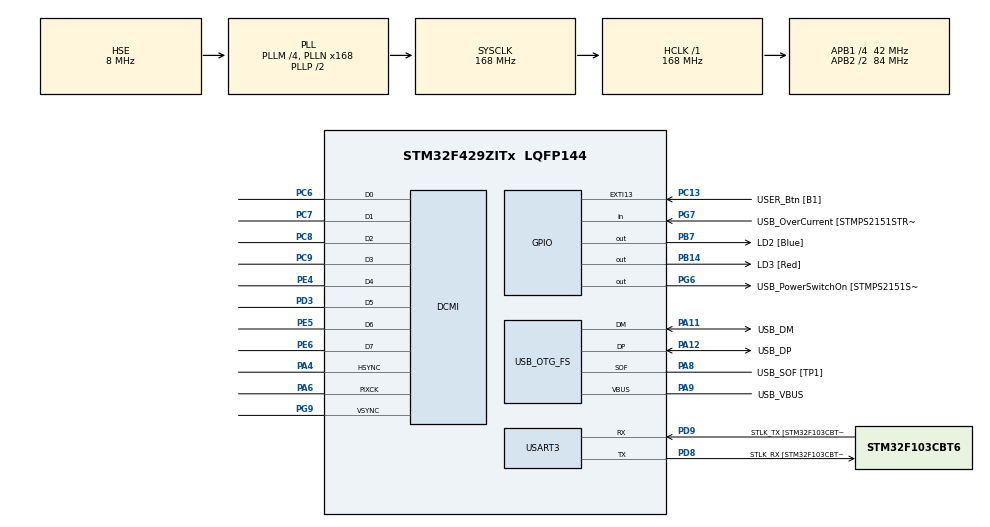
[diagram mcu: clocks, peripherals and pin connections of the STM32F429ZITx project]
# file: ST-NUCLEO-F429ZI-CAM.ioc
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Mcu.Family=STM32F4
Mcu.Name=STM32F429ZITx
Mcu.Package=LQFP144
NVIC.PriorityGroup=NVIC_PRIORITYGROUP_4
PA11.GPIO_Label=USB_DM
PA11.Mode=Device_Only
PA11.Signal=USB_OTG_FS_DM
PA12.GPIO_Label=USB_DP
PA12.Mode=Device_Only
PA12.Signal=USB_OTG_FS_DP
PA13.GPIO_Label=TMS
PA13.Mode=Serial_Wire
PA13.Signal=SYS_JTMS-SWDIO
PA14.GPIO_Label=TCK
PA14.Mode=Serial_Wire
PA14.Signal=SYS_JTCK-SWCLK
PA4.Mode=Slave_8_bits_External_Synchro
PA4.Signal=DCMI_HSYNC
PA6.Mode=Slave_8_bits_External_Synchro
PA6.Signal=DCMI_PIXCK
PA8.GPIO_Label=USB_SOF [TP1]
PA8.Mode=Activate_SOF_FS
PA8.Signal=USB_OTG_FS_SOF
PA9.GPIO_Label=USB_VBUS
PA9.Mode=Activate_VBUS
PA9.Signal=USB_OTG_FS_VBUS
PB14.GPIO_Label=LD3 [Red]
PB14.Signal=GPIO_Output
PB7.GPIO_Label=LD2 [Blue]
PB7.Signal=GPIO_Output
PC13.GPIO_Label=USER_Btn [B1]
PC13.Signal=GPXTI13
PC14/OSC32_IN.Mode=LSE-External-Oscillator
PC14/OSC32_IN.Signal=RCC_OSC32_IN
PC15/OSC32_OUT.Mode=LSE-External-Oscillator
PC15/OSC32_OUT.Signal=RCC_OSC32_OUT
PC6.Mode=Slave_8_bits_External_Synchro
PC6.Signal=DCMI_D0
PC7.Mode=Slave_8_bits_External_Synchro
PC7.Signal=DCMI_D1
PC8.Mode=Slave_8_bits_External_Synchro
PC8.Signal=DCMI_D2
PC9.Mode=Slave_8_bits_External_Synchro
PC9.Signal=DCMI_D3
PD3.Mode=Slave_8_bits_External_Synchro
PD3.Signal=DCMI_D5
PD8.GPIO_Label=STLK_RX [STM32F103CBT6_PA3]
PD8.Mode=Asynchronous
PD8.Signal=USART3_TX
PD9.GPIO_Label=STLK_TX [STM32F103CBT6_PA2]
PD9.Mode=Asynchronous
PD9.Signal=USART3_RX
PE4.Mode=Slave_8_bits_External_Synchro
PE4.Signal=DCMI_D4
PE5.Mode=Slave_8_bits_External_Synchro
PE5.Signal=DCMI_D6
PE6.Mode=Slave_8_bits_External_Synchro
PE6.Signal=DCMI_D7
PG6.GPIO_Label=USB_PowerSwitchOn [STMPS2151STR_EN]
PG6.Signal=GPIO_Output
PG7.GPIO_Label=USB_OverCurrent [STMPS2151STR_FAULT]
PG7.Signal=GPIO_Input
PG9.Mode=Slave_8_bits_External_Synchro
PG9.Signal=DCMI_VSYNC
PH0/OSC_IN.GPIO_Label=MCO [STM32F103CBT6_PA8]
PH0/OSC_IN.Mode=HSE-External-Clock-Source
PH0/OSC_IN.Signal=RCC_OSC_IN
PH1/OSC_OUT.Mode=HSE-External-Clock-Source
PH1/OSC_OUT.Signal=RCC_OSC_OUT
ProjectManager.HeapSize=0x1200
ProjectManager.StackSize=0x1400
ProjectManager.TargetToolchain=MDK-ARM V5
RCC.48MHZClocksFreq_Value=48000000
RCC.AHBFreq_Value=168000000
RCC.APB1CLKDivider=RCC_HCLK_DIV4
RCC.APB1Freq_Value=42000000
RCC.APB1TimFreq_Value=84000000
RCC.APB2CLKDivider=RCC_HCLK_DIV2
RCC.APB2Freq_Value=84000000
RCC.APB2TimCLKDivider=2
RCC.APB2TimFreq_Value=168000000
RCC.CortexFreq_Value=168000000
RCC.HCLKFreq_Value=168000000
RCC.HSE_VALUE=8000000
RCC.HSI_VALUE=16000000
RCC.PLLM=4
RCC.PLLMUL=RCC_PLL_MUL9
RCC.PLLN=168
RCC.PLLQ=7
RCC.PRESCALERUSB=RCC_USBCLKSOURCE_PLL_DIV1_5
RCC.SYSCLKFreq_VALUE=168000000
RCC.SYSCLKSource=RCC_SYSCLKSOURCE_PLLCLK
RCC.SYSCLKSourceVirtual=RCC_SYSCLKSOURCE_PLLCLK
RCC.USBFreq_Value=48000000
RCC.VCOOutputFreq_Value=336000000
USART3.VirtualMode=VM_ASYNC
USB_DEVICE.CLASS_NAME_FS=AUDIO
USB_DEVICE.VirtualMode-AUDIO_FS=Audio
USB_DEVICE.VirtualModeFS=Audio_FS
USB_OTG_FS.VirtualMode=Device_Only
VP_USB_DEVICE_VS_USB_DEVICE_AUDIO_FS.Mode=AUDIO_FS
board=NUCLEO-F429ZI

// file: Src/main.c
/* USER CODE BEGIN Header */
/**
  ******************************************************************************
  * @file           : main.c
  * @brief          : Main program body
  ******************************************************************************
  * @attention
  *
  * <h2><center>&copy; Copyright (c) 2019 STMicroelectronics.
  * All rights reserved.</center></h2>
  *
  * This software component is licensed by ST under Ultimate Liberty license
  * SLA0044, the "License"; You may not use this file except in compliance with
  * the License. You may obtain a copy of the License at:
  *                             www.st.com/SLA0044
  *
  ******************************************************************************
  */
/* USER CODE END Header */

#include "main.h"
#include "usb_device.h"

/* USER CODE BEGIN Includes */
#include <stdio.h>

/* USER CODE END Includes */

/* USER CODE BEGIN PTD */

#define FIRMWARE_VER			((const char *)"1.00r01")

#ifdef __GNUC__
	/* With GCC/RAISONANCE, small printf (option LD Linker->Libraries->Small printf
		 set to 'Yes') calls __io_putchar() */
	#define PUTCHAR_PROTOTYPE int __io_putchar(int ch)
#else
	#define PUTCHAR_PROTOTYPE int fputc(int ch, FILE *f)
#endif /* __GNUC__ */

/* USER CODE END PTD */

DCMI_HandleTypeDef hdcmi;

UART_HandleTypeDef huart3;

void SystemClock_Config(void);
static void MX_GPIO_Init(void);
static void MX_DCMI_Init(void);
static void MX_USART3_UART_Init(void);
/* USER CODE BEGIN PFP */

PUTCHAR_PROTOTYPE
{
	HAL_UART_Transmit(&huart3, (uint8_t *)&ch, 1, 0x0f);

  return ch;
}

/* USER CODE END PFP */

int main(void)
{

  /* MCU Configuration--------------------------------------------------------*/

  /* Reset of all peripherals, Initializes the Flash interface and the Systick. */
  HAL_Init();

  /* Configure the system clock */
  SystemClock_Config();

  /* Initialize all configured peripherals */
  MX_GPIO_Init();
  MX_DCMI_Init();
  MX_USART3_UART_Init();
  /* USER CODE BEGIN 2 */

	printf("\r\n\r\nUVC Camera Application Firmware v%s\r\n", FIRMWARE_VER);
  MX_USB_DEVICE_Init();

  /* USER CODE END 2 */

  /* Infinite loop */
  while (1)
  {

    /* USER CODE BEGIN 3 */
		HAL_GPIO_TogglePin(LD2_GPIO_Port, LD2_Pin);
		HAL_Delay(500);
  }
  /* USER CODE END 3 */
}

void SystemClock_Config(void)
{
  RCC_OscInitTypeDef RCC_OscInitStruct = {0};
  RCC_ClkInitTypeDef RCC_ClkInitStruct = {0};

  /** Configure the main internal regulator output voltage
  */
  __HAL_RCC_PWR_CLK_ENABLE();
  __HAL_PWR_VOLTAGESCALING_CONFIG(PWR_REGULATOR_VOLTAGE_SCALE1);
  /** Initializes the CPU, AHB and APB busses clocks
  */
  RCC_OscInitStruct.OscillatorType = RCC_OSCILLATORTYPE_HSE;
  RCC_OscInitStruct.HSEState = RCC_HSE_BYPASS;
  RCC_OscInitStruct.PLL.PLLState = RCC_PLL_ON;
  RCC_OscInitStruct.PLL.PLLSource = RCC_PLLSOURCE_HSE;
  RCC_OscInitStruct.PLL.PLLM = 4;
  RCC_OscInitStruct.PLL.PLLN = 168;
  RCC_OscInitStruct.PLL.PLLP = RCC_PLLP_DIV2;
  RCC_OscInitStruct.PLL.PLLQ = 7;
  if (HAL_RCC_OscConfig(&RCC_OscInitStruct) != HAL_OK)
  {
    Error_Handler();
  }
  /** Initializes the CPU, AHB and APB busses clocks
  */
  RCC_ClkInitStruct.ClockType = RCC_CLOCKTYPE_HCLK|RCC_CLOCKTYPE_SYSCLK
                              |RCC_CLOCKTYPE_PCLK1|RCC_CLOCKTYPE_PCLK2;
  RCC_ClkInitStruct.SYSCLKSource = RCC_SYSCLKSOURCE_PLLCLK;
  RCC_ClkInitStruct.AHBCLKDivider = RCC_SYSCLK_DIV1;
  RCC_ClkInitStruct.APB1CLKDivider = RCC_HCLK_DIV4;
  RCC_ClkInitStruct.APB2CLKDivider = RCC_HCLK_DIV2;

  if (HAL_RCC_ClockConfig(&RCC_ClkInitStruct, FLASH_LATENCY_5) != HAL_OK)
  {
    Error_Handler();
  }
}

static void MX_DCMI_Init(void)
{

  hdcmi.Instance = DCMI;
  hdcmi.Init.SynchroMode = DCMI_SYNCHRO_HARDWARE;
  hdcmi.Init.PCKPolarity = DCMI_PCKPOLARITY_FALLING;
  hdcmi.Init.VSPolarity = DCMI_VSPOLARITY_LOW;
  hdcmi.Init.HSPolarity = DCMI_HSPOLARITY_LOW;
  hdcmi.Init.CaptureRate = DCMI_CR_ALL_FRAME;
  hdcmi.Init.ExtendedDataMode = DCMI_EXTEND_DATA_8B;
  hdcmi.Init.JPEGMode = DCMI_JPEG_DISABLE;
  if (HAL_DCMI_Init(&hdcmi) != HAL_OK)
  {
    Error_Handler();
  }

}

static void MX_USART3_UART_Init(void)
{

  huart3.Instance = USART3;
  huart3.Init.BaudRate = 115200;
  huart3.Init.WordLength = UART_WORDLENGTH_8B;
  huart3.Init.StopBits = UART_STOPBITS_1;
  huart3.Init.Parity = UART_PARITY_NONE;
  huart3.Init.Mode = UART_MODE_TX_RX;
  huart3.Init.HwFlowCtl = UART_HWCONTROL_NONE;
  huart3.Init.OverSampling = UART_OVERSAMPLING_16;
  if (HAL_UART_Init(&huart3) != HAL_OK)
  {
    Error_Handler();
  }

}

static void MX_GPIO_Init(void)
{
  GPIO_InitTypeDef GPIO_InitStruct = {0};

  /* GPIO Ports Clock Enable */
  __HAL_RCC_GPIOE_CLK_ENABLE();
  __HAL_RCC_GPIOC_CLK_ENABLE();
  __HAL_RCC_GPIOH_CLK_ENABLE();
  __HAL_RCC_GPIOA_CLK_ENABLE();
  __HAL_RCC_GPIOB_CLK_ENABLE();
  __HAL_RCC_GPIOD_CLK_ENABLE();
  __HAL_RCC_GPIOG_CLK_ENABLE();

  /*Configure GPIO pin Output Level */
  HAL_GPIO_WritePin(GPIOB, LD3_Pin|LD2_Pin, GPIO_PIN_RESET);

  /*Configure GPIO pin Output Level */
  HAL_GPIO_WritePin(USB_PowerSwitchOn_GPIO_Port, USB_PowerSwitchOn_Pin, GPIO_PIN_RESET);

  /*Configure GPIO pin : USER_Btn_Pin */
  GPIO_InitStruct.Pin = USER_Btn_Pin;
  GPIO_InitStruct.Mode = GPIO_MODE_IT_RISING;
  GPIO_InitStruct.Pull = GPIO_NOPULL;
  HAL_GPIO_Init(USER_Btn_GPIO_Port, &GPIO_InitStruct);

  /*Configure GPIO pins : LD3_Pin LD2_Pin */
  GPIO_InitStruct.Pin = LD3_Pin|LD2_Pin;
  GPIO_InitStruct.Mode = GPIO_MODE_OUTPUT_PP;
  GPIO_InitStruct.Pull = GPIO_NOPULL;
  GPIO_InitStruct.Speed = GPIO_SPEED_FREQ_LOW;
  HAL_GPIO_Init(GPIOB, &GPIO_InitStruct);

  /*Configure GPIO pin : USB_PowerSwitchOn_Pin */
  GPIO_InitStruct.Pin = USB_PowerSwitchOn_Pin;
  GPIO_InitStruct.Mode = GPIO_MODE_OUTPUT_PP;
  GPIO_InitStruct.Pull = GPIO_NOPULL;
  GPIO_InitStruct.Speed = GPIO_SPEED_FREQ_LOW;
  HAL_GPIO_Init(USB_PowerSwitchOn_GPIO_Port, &GPIO_InitStruct);

  /*Configure GPIO pin : USB_OverCurrent_Pin */
  GPIO_InitStruct.Pin = USB_OverCurrent_Pin;
  GPIO_InitStruct.Mode = GPIO_MODE_INPUT;
  GPIO_InitStruct.Pull = GPIO_NOPULL;
  HAL_GPIO_Init(USB_OverCurrent_GPIO_Port, &GPIO_InitStruct);

}

void Error_Handler(void)
{
}

/************************ (C) COPYRIGHT STMicroelectronics *****END OF FILE****/
